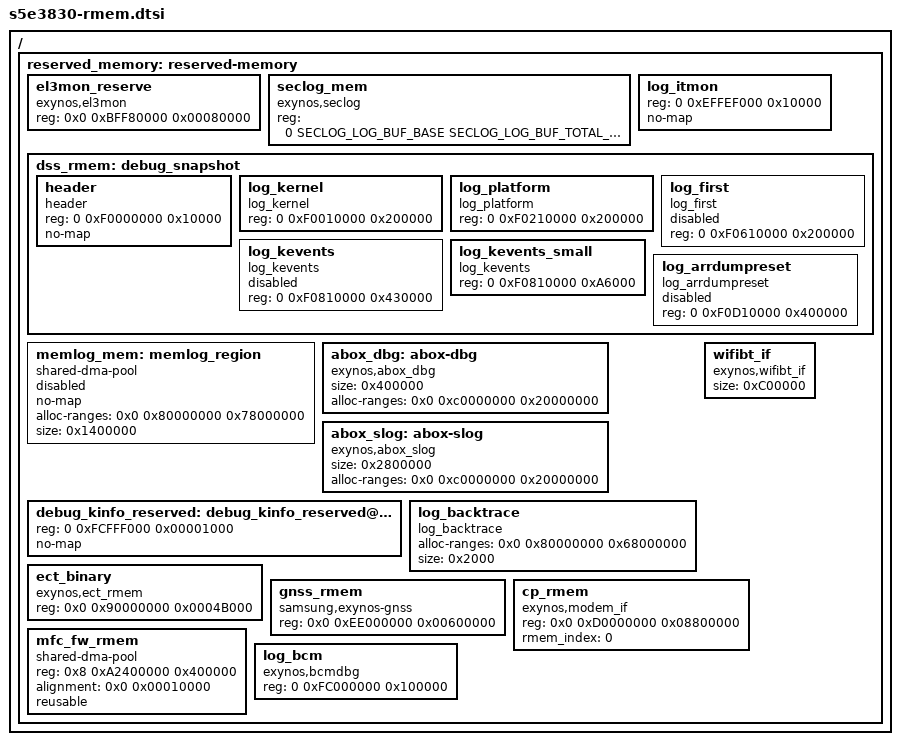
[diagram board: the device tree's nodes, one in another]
/*
 * SAMSUNG EXYNOS device tree source for reserved-memory
 *
 * Copyright (c) 2022 Samsung Electronics Co., Ltd.
 *             http://www.samsung.com
 *
 * This program is free software; you can redistribute it and/or modify
 * it under the terms of the GNU General Public License version 2 as
 * published by the Free Software Foundation.
 */
#include <dt-bindings/soc/samsung/s5e3830-seclog.h>

/ {
	reserved_memory: reserved-memory {
		#address-cells = <2>;
		#size-cells = <1>;
		ranges;

		el3mon_reserve {
			compatible = "exynos,el3mon";
			reg = <0x0 0xBFF80000 0x00080000>;
		};

		seclog_mem: seclog_mem {
		    compatible = "exynos,seclog";
		    reg = <0 SECLOG_LOG_BUF_BASE SECLOG_LOG_BUF_TOTAL_SIZE>;
		};

		log_itmon: log_itmon {
			reg = <0 0xEFFEF000 0x10000>;
			no-map;
		};

                dss_rmem: debug_snapshot {
                        #address-cells = <2>;
                        #size-cells = <1>;
                        header: header {
				compatible = "header";
                                reg = <0 0xF0000000 0x10000>;
				no-map;
                        };
                        log_kernel: log_kernel {
				compatible = "log_kernel";
                                reg = <0 0xF0010000 0x200000>;
                        };
			log_platform: log_platform {
				compatible = "log_platform";
				reg = <0 0xF0210000 0x200000>;
			};
                        log_first: log_first {
				compatible = "log_first";
				reg = <0 0xF0610000 0x200000>;
				status = "no";
                        };
			log_kevents: log_kevents {
				compatible = "log_kevents";
				reg = <0 0xF0810000 0x430000>;
				status = "no";
			};
			log_kevents_small: log_kevents_small {
				compatible = "log_kevents";
				reg = <0 0xF0810000 0xA6000>;
			};
			log_arrdumpreset: log_arrdumpreset {
				compatible = "log_arrdumpreset";
				reg = <0 0xF0D10000 0x400000>;
				status = "no";
			};
                };

		memlog_mem: memlog_region {
			compatible = "shared-dma-pool";
			no-map;
			alloc-ranges = <0x0 0x80000000 0x78000000>;
			size = <0x1400000>;
			status = "no";
		};

		abox_dbg: abox-dbg {
			compatible = "exynos,abox_dbg";
			size = <0x400000>;
			alloc-ranges = <0x0 0xc0000000 0x20000000>;
		};

		abox_slog: abox-slog {
			compatible = "exynos,abox_slog";
			size = <0x2800000>;
			alloc-ranges = <0x0 0xc0000000 0x20000000>;
		};

		debug_kinfo_reserved: debug_kinfo_reserved@fcfff000 {
			reg = <0 0xFCFFF000 0x00001000>;
			no-map;
		};

                log_backtrace: log_backtrace {
			compatible = "log_backtrace";
			alloc-ranges = <0x0 0x80000000 0x68000000>;
			size = <0x2000>;
		};

		ect_binary: ect_binary {
			compatible = "exynos,ect_rmem";
			reg = <0x0 0x90000000 0x0004B000>;
		};

		wifibt_if: wifibt_if {
			compatible = "exynos,wifibt_if";
			size = <0xC00000>; /* 12MB */
		};

		gnss_rmem: gnss_rmem {
			compatible = "samsung,exynos-gnss";
			reg = <0x0 0xEE000000 0x00600000>;
		};

		cp_rmem: cp_rmem {
			compatible = "exynos,modem_if";
			reg = <0x0 0xD0000000 0x08800000>;
			rmem_index = <0>;
		};

		mfc_fw_rmem: mfc_fw_rmem {
			compatible = "shared-dma-pool";
			reg = <0x8 0xA2400000 0x400000>;
			alignment = <0x0 0x00010000>;
			reusable;
		};

		/* fb_handover shall be removed in DPU command mode
		 * operation. Otherwise, It will end up in waste of memory
		 */
		/*
		fb_handover: fb_handover {
		compatible = "exynos,fb_handover";
		reg = <0x0 0xF9800000 0x02800000>;
		};
		*/

		log_bcm: log_bcm {
			compatible = "exynos,bcmdbg";
			reg = <0 0xFC000000 0x100000>;
		};
	};
};
